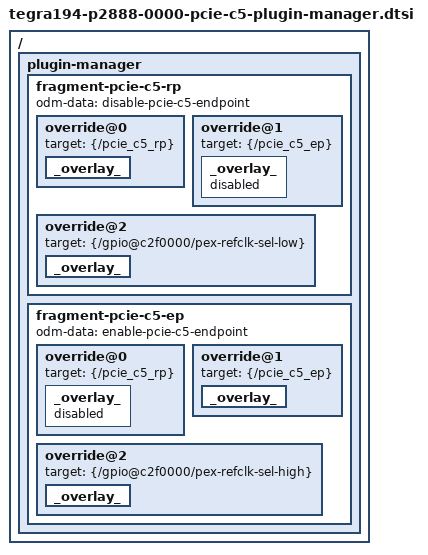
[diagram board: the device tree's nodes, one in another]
/*
 * Copyright (c) 2018, NVIDIA CORPORATION.  All rights reserved.
 *
 * This program is free software; you can redistribute it and/or modify
 * it under the terms of the GNU General Public License as published by
 * the Free Software Foundation; either version 2 of the License, or
 * (at your option) any later version.
 *
 * This program is distributed in the hope that it will be useful, but WITHOUT
 * ANY WARRANTY; without even the implied warranty of MERCHANTABILITY or
 * FITNESS FOR A PARTICULAR PURPOSE.  See the GNU General Public License for
 * more details.
 */

/ {
	plugin-manager {
		fragment-pcie-c5-rp {
			odm-data = "disable-pcie-c5-endpoint";
			override@0 {
				target = <&{/pcie_c5_rp}>;
				_overlay_ {
					status = "okay";
				};
			};
			override@1 {
				target = <&{/pcie_c5_ep}>;
				_overlay_ {
					status = "disabled";
				};
			};
			override@2 {
				target = <&{/gpio@c2f0000/pex-refclk-sel-low}>;
				_overlay_ {
					status = "okay";
				};
			};
		};

		fragment-pcie-c5-ep {
			odm-data = "enable-pcie-c5-endpoint";
			override@0 {
				target = <&{/pcie_c5_rp}>;
				_overlay_ {
					status = "disabled";
				};
			};
			override@1 {
				target = <&{/pcie_c5_ep}>;
				_overlay_ {
					status = "okay";
				};
			};
			override@2 {
				target = <&{/gpio@c2f0000/pex-refclk-sel-high}>;
				_overlay_ {
					status = "okay";
				};
			};
		};
	};
};
